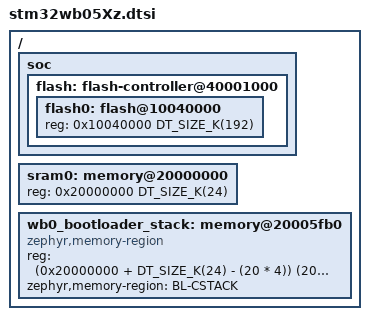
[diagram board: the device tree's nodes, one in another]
/*
 * Copyright (c) 2024 STMicroelectronics
 *
 * SPDX-License-Identifier: Apache-2.0
 */

#include <st/wb0/stm32wb05.dtsi>

/ {
	soc {
		flash: flash-controller@40001000 {
			flash0: flash@10040000 {
				reg = <0x10040000 DT_SIZE_K(192)>;
			};
		};
	};

	sram0: memory@20000000 {
		reg = <0x20000000 DT_SIZE_K(24)>;
	};

	wb0_bootloader_stack: memory@20005fb0 {
		compatible = "zephyr,memory-region";
		reg = <(0x20000000 + DT_SIZE_K(24) - (20 * 4)) (20 * 4)>;
		zephyr,memory-region = "BL-CSTACK";
	};
};
